# ipro6s register map
Vendor: intelpro; Series: IPRO6S
CPU: ipro6s, little endian
Registers are 32-bit, read-write, reset 0x0 unless marked. A register's access mark holds for its fields unless they carry their own. Offsets are from the block's base; [hi:lo] are bit positions; {n}, {i} and the like mark numbered series.

## RF_EPA
Base 0x30001000
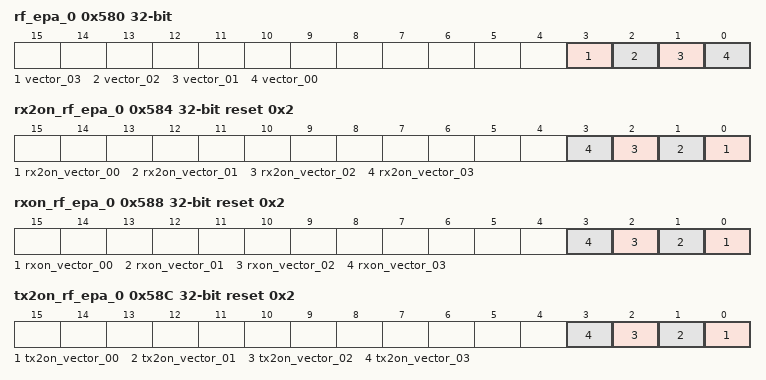
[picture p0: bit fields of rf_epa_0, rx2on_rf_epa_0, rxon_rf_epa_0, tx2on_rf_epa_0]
0x580 rf_epa_0
  [3] vector_03 — reservd
  [2] vector_02 — reservd
  [1] vector_01 — FEM_GPIO1
  [0] vector_00 — FEM_GPIO0
0x584 rx2on_rf_epa_0 reset 0x2
  [n] rx2on_vector_{n:02} (n=0..3)
0x588 rxon_rf_epa_0 reset 0x2
  [n] rxon_vector_{n:02} (n=0..3)
0x58C tx2on_rf_epa_0 reset 0x2
  [n] tx2on_vector_{n:02} (n=0..3)
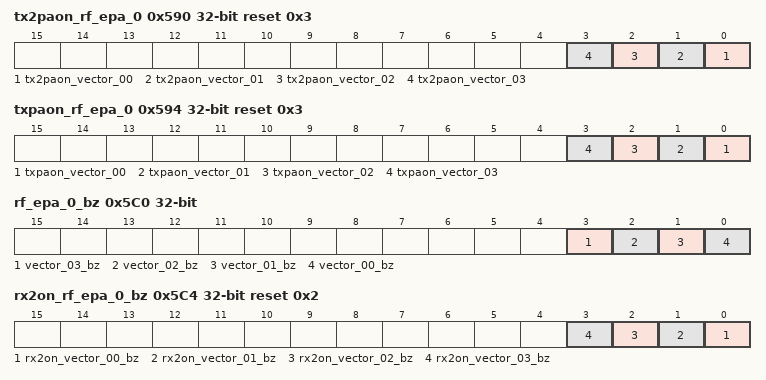
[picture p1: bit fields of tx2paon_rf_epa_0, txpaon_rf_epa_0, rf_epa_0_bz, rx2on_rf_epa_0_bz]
0x590 tx2paon_rf_epa_0 reset 0x3
  [n] tx2paon_vector_{n:02} (n=0..3)
0x594 txpaon_rf_epa_0 reset 0x3
  [n] txpaon_vector_{n:02} (n=0..3)
0x5C0 rf_epa_0_bz
  [3] vector_03_bz — reservd
  [2] vector_02_bz — reservd
  [1] vector_01_bz — FEM_GPIO1
  [0] vector_00_bz — FEM_GPIO0
0x5C4 rx2on_rf_epa_0_bz reset 0x2
  [n] rx2on_vector_{n:02}_bz (n=0..3)
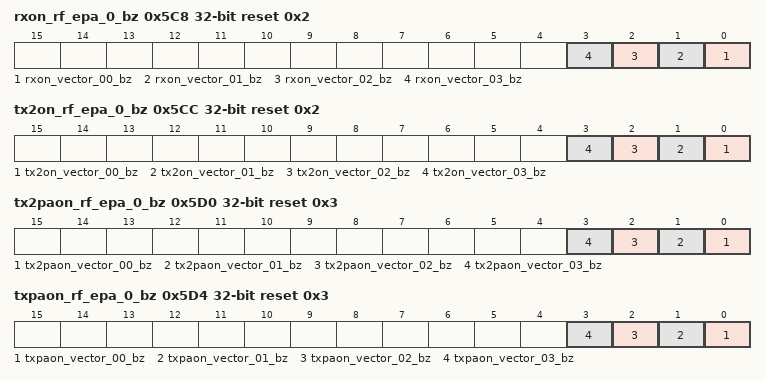
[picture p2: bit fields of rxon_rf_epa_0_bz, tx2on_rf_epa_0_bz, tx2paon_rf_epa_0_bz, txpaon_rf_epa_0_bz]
0x5C8 rxon_rf_epa_0_bz reset 0x2
  [n] rxon_vector_{n:02}_bz (n=0..3)
0x5CC tx2on_rf_epa_0_bz reset 0x2
  [n] tx2on_vector_{n:02}_bz (n=0..3)
0x5D0 tx2paon_rf_epa_0_bz reset 0x3
  [n] tx2paon_vector_{n:02}_bz (n=0..3)
0x5D4 txpaon_rf_epa_0_bz reset 0x3
  [n] txpaon_vector_{n:02}_bz (n=0..3)

## GPIP
Base 0x30002000
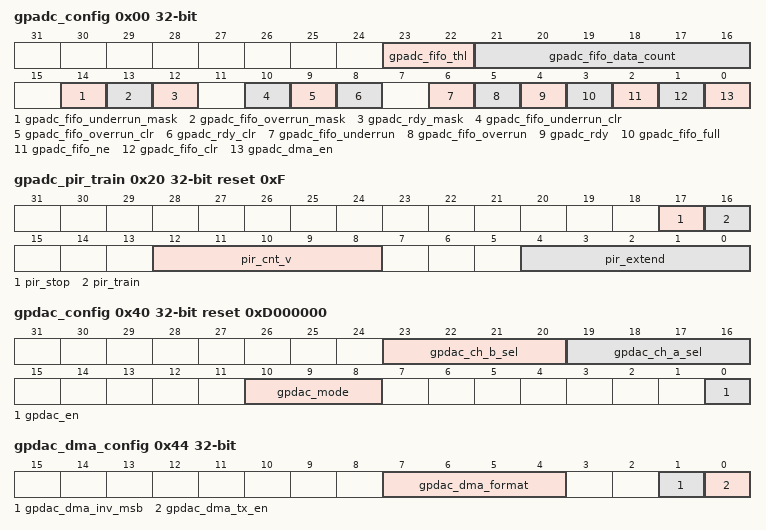
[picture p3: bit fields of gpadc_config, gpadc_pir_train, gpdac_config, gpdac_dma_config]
0x00 gpadc_config (reset mask 0xFFC07703)
  [23:22] gpadc_fifo_thl — fifo threshold 2'b00: 1 data 2'b01: 4 data 2'b10: 8 data 2'b11: 16 data
  [21:16] gpadc_fifo_data_count ro — fifo data number
  [14] gpadc_fifo_underrun_mask — write 1 mask
  [13] gpadc_fifo_overrun_mask — write 1 mask
  [12] gpadc_rdy_mask — write 1 mask
  [10] gpadc_fifo_underrun_clr — Write 1 to clear flag
  [9] gpadc_fifo_overrun_clr — Write 1 to clear flag
  [8] gpadc_rdy_clr — Write 1 to clear flag
  [6] gpadc_fifo_underrun ro — FIFO underrun interrupt flag
  [5] gpadc_fifo_overrun ro — FIFO overrun interrupt flag
  [4] gpadc_rdy ro — Conversion data ready interrupt flag
  [3] gpadc_fifo_full ro — FIFO full flag
  [2] gpadc_fifo_ne ro — FIFO not empty flag
  [1] gpadc_fifo_clr wo — FIFO clear signal
  [0] gpadc_dma_en — GPADC DMA enbale
0x04 gpadc_dma_rdata (reset mask 0xFC000000)
  [25:0] gpadc_dma_rdata ro — GPADC finial conversion result stored in the FIFO
0x20 gpadc_pir_train reset 0xF (reset mask 0x1001F)
  [17] pir_stop ro — PIR Training End
  [16] pir_train — PIR Training Mode
  [12:8] pir_cnt_v ro — GPADC Record Extension Counter Value
  [4:0] pir_extend — GPADC Record Extension after PIR interrupt
0x40 gpdac_config reset 0xD000000
  [23:20] gpdac_ch_b_sel — Channel B Source Select 0: Reg 1: DMA 2: DMA + Filter 3: Sin Gen 4: A (The same as channel A) 5: ~A (Inverse of channel A)
  [19:16] gpdac_ch_a_sel — Channel A Source Select 0: Reg 1: DMA 2: DMA + Filter 3: Sin Gen
  [10:8] gpdac_mode — 0:32k, 1:16k, 3:8k, 4:512k(for DMA only)
  [0] gpdac_en — GPDAC enable
0x44 gpdac_dma_config
  [7:4] gpdac_dma_format — DMA TX format (Data 12-bit) 0: ([11:0]) {A0}, {A1}, {A2}… 1: ([27:16][11:0]) {B0,A0}, {B1,A1}, {B2,A2}… 2: ([27:16][11:0]) {A1,A0}, {A3,A2}, {A5,A4}… 4: ([15:4]) {A0}, {A1}, {A2}… 5: ([31:20][15:4]) {B0,A0}, {B1,A1}, {B2,A2}… 6: ([31:20][15:4]) {A1,A0}, {A3,A2}, {A5,A4}… 8: ([31:24][23:16][15:8][7:0]) {A3,A2,A1,A0}, {A7,A6,A5,A4}… 9: ([31:24][23:16][15:8][7:0]) {B1,B0,A1,A0}, {B3,B2,A3,A2}… 10: ([31:24][23:16][15:8][7:0]) {B1,A1,B0,A0}, {B3,A3,B2,A2}… 11: ([15:8][7:0]) {B0,A0}, {B1,A1}, {B2,A2}…
  [1] gpdac_dma_inv_msb — GPDAC DMA Data Inverse MSB
  [0] gpdac_dma_tx_en — GPDAC DMA TX enable
0x48 gpdac_dma_wdata
  [31:0] gpdac_dma_wdata wo — GPDAC DMA TX data
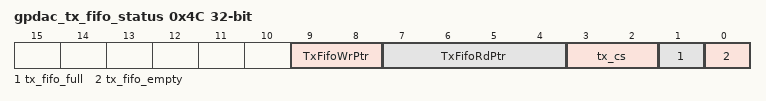
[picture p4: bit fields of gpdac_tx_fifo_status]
0x4C gpdac_tx_fifo_status reset not defined
  [9:8] TxFifoWrPtr ro, [7:4] TxFifoRdPtr ro, [3:2] tx_cs ro, [1] tx_fifo_full ro, [0] tx_fifo_empty ro

## SEC_DBG
Base 0x30005000
0x00 sd_chip_id_low reset not defined
  [31:0] sd_chip_id_low ro
0x04 sd_chip_id_high reset not defined
  [31:0] sd_chip_id_high ro
0x08 sd_dbg_pwd_low
0x0C sd_dbg_pwd_high
0x10 sd_dbg_pwd2_low
0x14 sd_dbg_pwd2_high
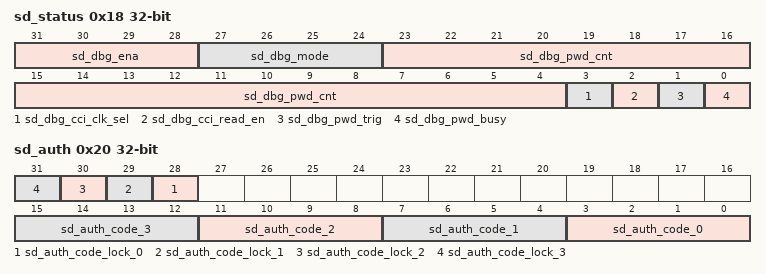
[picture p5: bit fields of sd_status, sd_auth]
0x18 sd_status (reset mask 0xE)
  [31:28] sd_dbg_ena ro, [27:24] sd_dbg_mode ro, [23:4] sd_dbg_pwd_cnt ro, [3] sd_dbg_cci_clk_sel, [2] sd_dbg_cci_read_en, [1] sd_dbg_pwd_trig, [0] sd_dbg_pwd_busy ro
0x1C sd_dbg_reserved reset 0xFFFF
0x20 sd_auth (reset mask 0xFFFF)
  [n+28] sd_auth_code_lock_{n} ro (n=0..3), [4n+3:4n] sd_auth_code_{n} (n=0..3)
